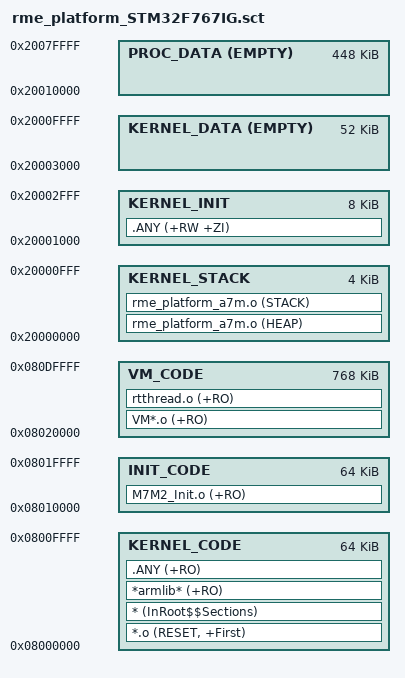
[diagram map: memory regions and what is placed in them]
;******************************************************************************
;Filename    : rme_platform_STM32F767IG.sct
;Author      : pry
;Date        : 24/06/2017
;Licence     : LGPL v3+; see COPYING for details.
;Description : The scatter file for Cortex-M7 layout. This file is intended 
;              to be used with STM32F767IGT6.
;              ROM: 0x08000000 0x00100000
;              RAM: 0x20000000 0x00080000
;              System ROM layout:
;              |0x08000000            0x0800FFFF|0x08010000         0x080FFFFF|
;              |<-           Kernel           ->|<-           User          ->|
;              System RAM layout:
;              |0x20000000            0x20001FFF|0x20002000         0x20003FFF|
;              |<-        Kernel Stack        ->|<-        Kernel Data      ->|
;              |0x20004000            0x2000FFFF|0x20010000         0x2007FFFF|
;              |<-       Kernel Objects       ->|<-           User          ->|
;******************************************************************************

; Begin Segment:KERNEL ********************************************************
; Description : The kernel segment, this is where the kernel of the operating
;               system is located at. This segment also contains the .bss(ZI)
;               for processes.
; *****************************************************************************
KERNEL 0x08000000 0x00010000
{   
    ; Kernel code segment - 64kB
    KERNEL_CODE 0x08000000 0x00010000
    {   ; The reset vectors
        *.o                            (RESET, +First)
        ; The lib code copying code
        *                              (InRoot$$Sections)
        ; The ARM C library code - all of them is here
        *armlib*                       (+RO)
        ; The kernel code section
        .ANY                           (+RO)
    }
    
    ; Kernel stack segment - 4kB
    KERNEL_STACK 0x20000000 0x00001000
    {
        rme_platform_a7m.o                 (HEAP)
        rme_platform_a7m.o                 (STACK)
    }
    
    ; Initial kernel data segment - 8kB 
    KERNEL_INIT 0x20001000 0x00002000
    {
        .ANY                           (+RW +ZI)
    }
    
    ; Dynamically managed kernel data segment - 52kB
    KERNEL_DATA 0x20003000 EMPTY 0x0000D000
    {
        
    }
    ; The data section of the processes - The rest of the memory
    PROC_DATA 0x20010000 EMPTY 0x00070000
    {

    }
}
; End Segment:KERNEL **********************************************************

; Begin Segment:INIT **********************************************************
; Description : The .text segment of process INIT. Init is the first process
;               in the system, and should act as a memory manager itself.
;               The .RODATA size if this process is 0x00010000.
; *****************************************************************************
INIT 0x08010000 0x00010000
{
    ; Init process code segment - 64kB
    INIT_CODE 0x08010000 0x00010000
    {
        M7M2_Init.o                    (+RO)
    }
}
; End Segment:INIT ************************************************************

; Begin Segment:VM ************************************************************
; Description : The .text segment of the virtual machines. All virtual machines
; needs to be placed here; If you don't want to convert them to C and compile to
; a whole image, flash them to this address.
; *****************************************************************************
VM 0x08020000 0x000C0000
{
    ; Init process code segment - 64kB
    VM_CODE 0x08020000 0x000C0000
    {
        VM*.o                         (+RO)
        rtthread.o                    (+RO)
    }
}
; End Segment:VM **************************************************************

; End Of File *****************************************************************

; Copyright (C) Evo-Devo Instrum. All rights reserved *************************
